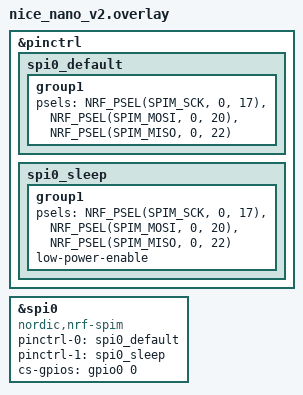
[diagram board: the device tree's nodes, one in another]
/* Define board hardware details. */

#include <dt-bindings/led/led.h>

/*
Set pins for

-   Bare LED
-   Smart LEDs
-   Display

Using two-part pin numbers at
https://nicekeyboards.com/docs/nice-nano/pinout-schematic/

Set type of bare LED, smart LED, and display.
*/


&pinctrl {

    // Display: on different SPI bus.
    spi0_default: spi0_default {
        group1 {
            psels = <NRF_PSEL(SPIM_SCK, 0, 17)>,
            <NRF_PSEL(SPIM_MOSI, 0, 20)>,
            <NRF_PSEL(SPIM_MISO, 0, 22)>; /* Optional. Not used by nice!view. */
        };
    };
    spi0_sleep: spi0_sleep {
        group1 {
            psels = <NRF_PSEL(SPIM_SCK, 0, 17)>,
            <NRF_PSEL(SPIM_MOSI, 0, 20)>,
            <NRF_PSEL(SPIM_MISO, 0, 22)>; /* Optional. Not used by nice!view. */
            low-power-enable;
        };
    };
};

/* SPI: Display */
nice_view_spi: &spi0 {
  compatible = "nordic,nrf-spim";
  pinctrl-0 = <&spi0_default>;
  pinctrl-1 = <&spi0_sleep>;
  pinctrl-names = "default", "sleep";
  cs-gpios = <&gpio0 0 GPIO_ACTIVE_HIGH>;
};

/ {
};
